VERSION "1.0"

NS_ :

BS_:

BU_: Engine_ECU Body_ECU Transmission_ECU

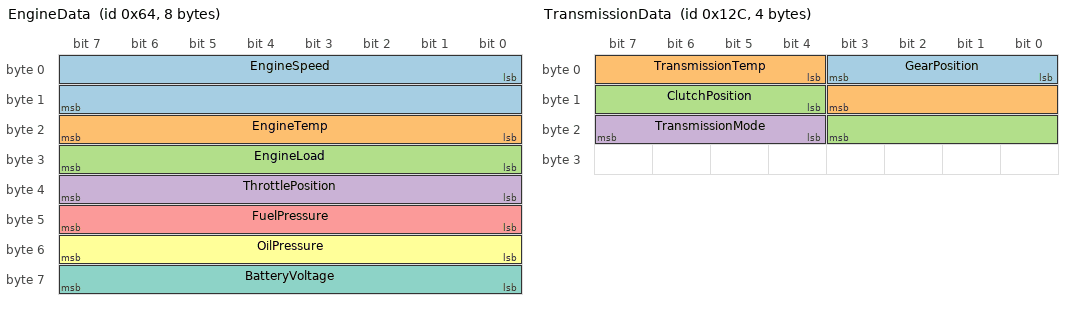
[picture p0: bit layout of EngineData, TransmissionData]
BO_ 100 EngineData: 8 Engine_ECU
 SG_ EngineSpeed : 0|16@1+ (0.125,0) [0|8031.875] "rpm" Engine_ECU
 SG_ EngineTemp : 16|8@1+ (1,-40) [-40|215] "degC" Engine_ECU
 SG_ EngineLoad : 24|8@1+ (0.392157,0) [0|100] "%" Engine_ECU
 SG_ ThrottlePosition : 32|8@1+ (0.392157,0) [0|100] "%" Engine_ECU
 SG_ FuelPressure : 40|8@1+ (0.1,0) [0|25.5] "bar" Engine_ECU
 SG_ OilPressure : 48|8@1+ (0.1,0) [0|25.5] "bar" Engine_ECU
 SG_ BatteryVoltage : 56|8@1+ (0.1,10) [10|15.5] "V" Engine_ECU

BO_ 200 VehicleData: 6 Body_ECU
 SG_ VehicleSpeed : 0|16@1+ (0.00390625,0) [0|255.996] "km/h" Body_ECU
 SG_ WheelSpeed_FL : 16|16@1+ (0.00390625,0) [0|255.996] "km/h" Body_ECU
 SG_ WheelSpeed_FR : 32|16@1+ (0.00390625,0) [0|255.996] "km/h" Body_ECU
 SG_ WheelSpeed_RL : 48|16@1+ (0.00390625,0) [0|255.996] "km/h" Body_ECU

BO_ 300 TransmissionData: 4 Transmission_ECU
 SG_ GearPosition : 0|4@1+ (1,0) [0|15] "" Transmission_ECU
 SG_ TransmissionTemp : 4|8@1+ (1,-40) [-40|215] "degC" Transmission_ECU
 SG_ ClutchPosition : 12|8@1+ (0.392157,0) [0|100] "%" Transmission_ECU
 SG_ TransmissionMode : 20|4@1+ (1,0) [0|15] "" Transmission_ECU

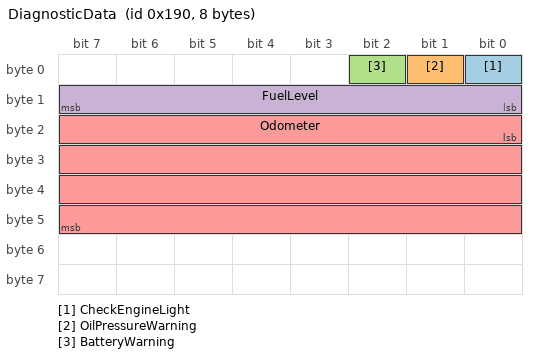
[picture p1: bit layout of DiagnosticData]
BO_ 400 DiagnosticData: 8 Engine_ECU
 SG_ CheckEngineLight : 0|1@1+ (1,0) [0|1] "" Engine_ECU
 SG_ OilPressureWarning : 1|1@1+ (1,0) [0|1] "" Engine_ECU
 SG_ BatteryWarning : 2|1@1+ (1,0) [0|1] "" Engine_ECU
 SG_ FuelLevel : 8|8@1+ (0.392157,0) [0|100] "%" Engine_ECU
 SG_ Odometer : 16|32@1+ (0.1,0) [0|429496729.5] "km" Engine_ECU

CM_ "Engine speed in RPM";
CM_ BO_ 100 "Engine data message";
CM_ SG_ 100 EngineSpeed "Engine speed in RPM";

VAL_TABLE_ GearPosition 0 "Neutral" 1 "1st" 2 "2nd" 3 "3rd" 4 "4th" 5 "5th" 6 "6th" 7 "Reverse" ;

VAL_TABLE_ TransmissionMode 0 "Manual" 1 "Automatic" 2 "Sport" 3 "Eco" ;

BA_DEF_ "BusType" STRING ;
BA_DEF_DEF_ "BusType" "CAN" ;
